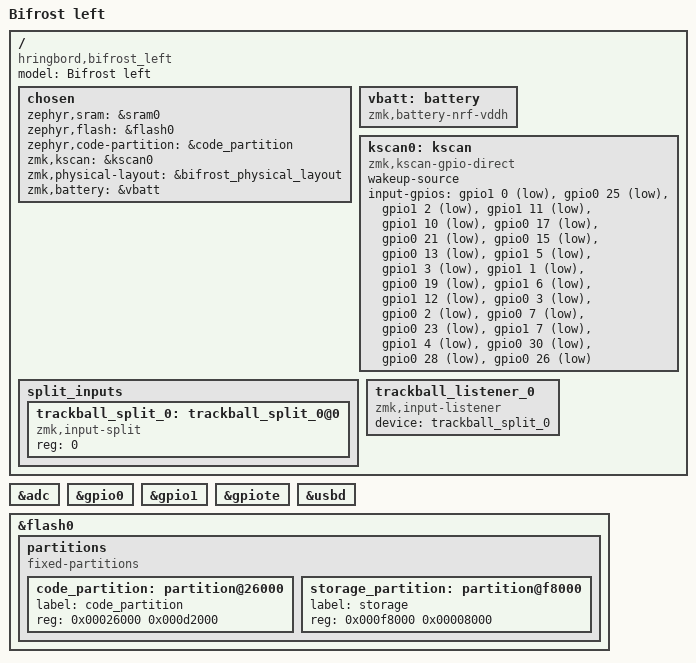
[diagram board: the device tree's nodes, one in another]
/*
 * Copyright (c) 2026 hringdrifi
 * SPDX-License-Identifier: MIT
 */

/dts-v1/;
#include <nordic/nrf52840_qiaa.dtsi>
#include <common/nordic/nrf52840_uf2_boot_mode.dtsi>
#include "../bifrost.dtsi"

/ {
    model = "Bifrost left";
    compatible = "hringbord,bifrost_left";

    chosen {
        zephyr,sram = &sram0;
        zephyr,flash = &flash0;
        zephyr,code-partition = &code_partition;
        zmk,kscan = &kscan0;
        zmk,physical-layout = &bifrost_physical_layout;
        zmk,battery = &vbatt;
    };

    vbatt: battery {
        compatible = "zmk,battery-nrf-vddh";
    };

    kscan0: kscan {
        compatible = "zmk,kscan-gpio-direct";
        wakeup-source;

        input-gpios
            = <&gpio1 0 (GPIO_ACTIVE_LOW | GPIO_PULL_UP)> /*  0: TAB  (P1.00) */
            , <&gpio0 25 (GPIO_ACTIVE_LOW | GPIO_PULL_UP)> /*  1: Q    (P0.25) */
            , <&gpio1 2 (GPIO_ACTIVE_LOW | GPIO_PULL_UP)> /*  2: W    (P1.02) */
            , <&gpio1 11 (GPIO_ACTIVE_LOW | GPIO_PULL_UP)> /*  3: E    (P1.11) */
            , <&gpio1 10 (GPIO_ACTIVE_LOW | GPIO_PULL_UP)> /*  4: R    (P1.10) */
            , <&gpio0 17 (GPIO_ACTIVE_LOW | GPIO_PULL_UP)> /*  5: T    (P0.17) */
            , <&gpio0 21 (GPIO_ACTIVE_LOW | GPIO_PULL_UP)> /*  6: CAPS (P0.21) */
            , <&gpio0 15 (GPIO_ACTIVE_LOW | GPIO_PULL_UP)> /*  7: A    (P0.15) */
            , <&gpio0 13 (GPIO_ACTIVE_LOW | GPIO_PULL_UP)> /*  8: S    (P0.13) */
            , <&gpio1 5 (GPIO_ACTIVE_LOW | GPIO_PULL_UP)> /*  9: D    (P1.05) */
            , <&gpio1 3 (GPIO_ACTIVE_LOW | GPIO_PULL_UP)> /* 10: F    (P1.03) */
            , <&gpio1 1 (GPIO_ACTIVE_LOW | GPIO_PULL_UP)> /* 11: G    (P1.01) */
            , <&gpio0 19 (GPIO_ACTIVE_LOW | GPIO_PULL_UP)> /* 12: MO1  (P0.19) */
            , <&gpio1 6 (GPIO_ACTIVE_LOW | GPIO_PULL_UP)> /* 13: Z    (P1.06) */
            , <&gpio1 12 (GPIO_ACTIVE_LOW | GPIO_PULL_UP)> /* 14: X    (P1.12) */
            , <&gpio0 3 (GPIO_ACTIVE_LOW | GPIO_PULL_UP)> /* 15: C    (P0.03) */
            , <&gpio0 2 (GPIO_ACTIVE_LOW | GPIO_PULL_UP)> /* 16: V    (P0.02) */
            , <&gpio0 7 (GPIO_ACTIVE_LOW | GPIO_PULL_UP)> /* 17: B    (P0.07) */
            , <&gpio0 23 (GPIO_ACTIVE_LOW | GPIO_PULL_UP)> /* 18: LCTL (P0.23) */
            , <&gpio1 7 (GPIO_ACTIVE_LOW | GPIO_PULL_UP)> /* 19: LGUI (P1.07) */
            , <&gpio1 4 (GPIO_ACTIVE_LOW | GPIO_PULL_UP)> /* 20: LALT (P1.04) */
            , <&gpio0 30 (GPIO_ACTIVE_LOW | GPIO_PULL_UP)> /* 21: BSPC (P0.30) */
            , <&gpio0 28 (GPIO_ACTIVE_LOW | GPIO_PULL_UP)> /* 22: SPC  (P0.28) */
            , <&gpio0 26 (GPIO_ACTIVE_LOW | GPIO_PULL_UP)> /* 23: DEL  (P0.26) */
            ;
    };


};
/ {
    split_inputs {
        #address-cells = <1>;
        #size-cells = <0>;

        trackball_split_0: trackball_split_0@0 {
            compatible = "zmk,input-split";
            reg = <0>;
        };
    };

    trackball_listener_0: trackball_listener_0 {
        compatible = "zmk,input-listener";
        status = "disabled";
        device = <&trackball_split_0>;
    };
};

&trackball_listener_0 {
    status = "okay";
};


&adc {
    status = "okay";
};



&gpio0 {
    status = "okay";
};

&gpio1 {
    status = "okay";
};

&gpiote {
    status = "okay";
};

zephyr_udc0: &usbd {
    status = "okay";
};

&flash0 {
    partitions {
        compatible = "fixed-partitions";
        #address-cells = <1>;
        #size-cells = <1>;

        code_partition: partition@26000 {
            label = "code_partition";
            reg = <0x00026000 0x000d2000>;
        };

        storage_partition: partition@f8000 {
            label = "storage";
            reg = <0x000f8000 0x00008000>;
        };
    };
};
